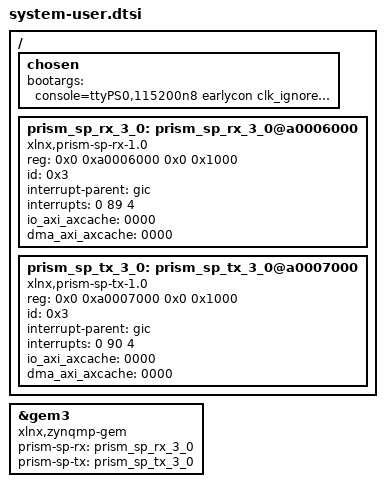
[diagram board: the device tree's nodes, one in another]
/include/ "system-conf.dtsi"
/ {
	chosen {
		bootargs = "console=ttyPS0,115200n8 earlycon clk_ignore_unused cpuidle.off=1";
	};

	prism_sp_rx_3_0: prism_sp_rx_3_0@a0006000 {
		#address-cells = <2>;
		#size-cells = <2>;

		compatible = "xlnx,prism-sp-rx-1.0";
		reg = <0x0 0xa0006000 0x0 0x1000>;
		reg-names = "mmr";
		id = <0x3>;
		interrupt-parent = <&gic>;
		interrupts = <0 89 4>;
		io_axi_axcache = "0000";
		dma_axi_axcache = "0000";
	};
	prism_sp_tx_3_0: prism_sp_tx_3_0@a0007000 {
		#address-cells = <2>;
		#size-cells = <2>;

		compatible = "xlnx,prism-sp-tx-1.0";
		reg = <0x0 0xa0007000 0x0 0x1000>;
		reg-names = "mmr";
		id = <0x3>;
		interrupt-parent = <&gic>;
		interrupts = <0 90 4>;
		io_axi_axcache = "0000";
		dma_axi_axcache = "0000";
	};
};

&gem3 {
	compatible = "xlnx,zynqmp-gem";
	prism-sp-rx = <&prism_sp_rx_3_0>;
	prism-sp-tx = <&prism_sp_tx_3_0>;
};

